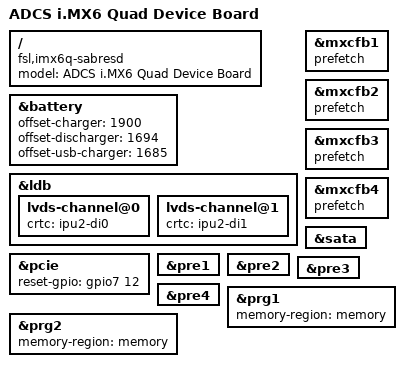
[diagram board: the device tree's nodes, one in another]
/*
 * Copyright (C) 2015 Freescale Semiconductor, Inc.
 *
 * This program is free software; you can redistribute it and/or modify
 * it under the terms of the GNU General Public License version 2 as
 * published by the Free Software Foundation.
 */

/dts-v1/;

#include "imx6q.dtsi"
#include "imx6q-adcs.dtsi"

/ {
	model = "ADCS i.MX6 Quad Device Board";
	compatible = "fsl,imx6q-sabresd", "fsl,imx6q";
};

&battery {
	offset-charger = <1900>;
	offset-discharger = <1694>;
	offset-usb-charger = <1685>;
};

&ldb {
	lvds-channel@0 {
		crtc = "ipu2-di0";
	};

	lvds-channel@1 {
		crtc = "ipu2-di1";
	};
};

&mxcfb1 {
	status = "okay";
};

&mxcfb2 {
	status = "okay";
};

&mxcfb3 {
	status = "okay";
};

&mxcfb4 {
	status = "okay";
};

&sata {
	status = "okay";
};

 
#include "imx6qp.dtsi"


 

&mxcfb1 {
	prefetch;
};

&mxcfb2 {
	prefetch;
};

&mxcfb3 {
	prefetch;
};

&mxcfb4 {
	prefetch;
};

 
&pcie {
	reset-gpio = <&gpio7 12 0>;
	status = "okay";
};

&pre1 {
	status = "okay";
};

&pre2 {
	status = "okay";
};

&pre3 {
	status = "okay";
};

&pre4 {
	status = "okay";
};

&prg1 {
	memory-region = <&memory>;
	status = "okay";
};

&prg2 {
	memory-region = <&memory>;
	status = "okay";
};

&sata {
	status = "okay";
};
